# f28p65x_trig_regs register map
Vendor: Texas Instruments
Peripheral module from a debugger description file (folder C2000).
Address unit: 16 bits
Registers are 32-bit, read-write, no defined reset value unless marked. A register's access mark holds for its fields unless they carry their own. Offsets are as the file gives them; lines under a group give offsets from that group; [hi:lo] are bit positions; {n}, {i} and the like mark numbered series; 'fields as' and 'values as' point back to an identical list; <NAME> marks a mode.

## TRIG_REGS — TRIG Registers
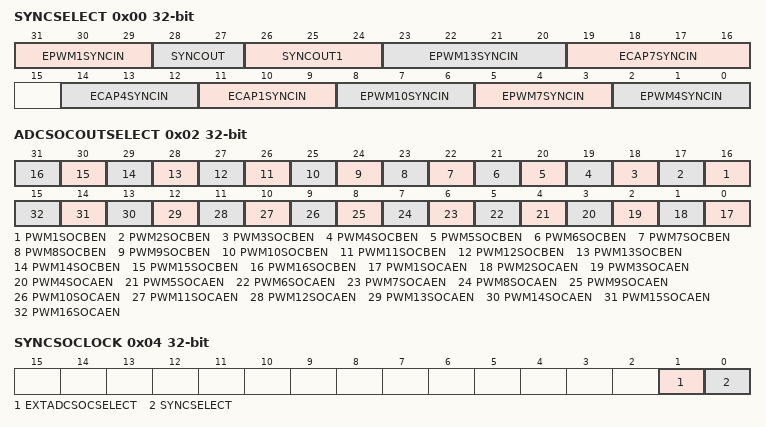
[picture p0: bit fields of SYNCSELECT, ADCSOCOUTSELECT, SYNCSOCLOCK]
0x00 SYNCSELECT — Sync Input and Output Select Register
  [31:29] EPWM1SYNCIN — Selects Sync Input Source for EPWM1
  [28:27] SYNCOUT — Select Syncout Source
  [26:24] SYNCOUT1 — Select Syncout Source
  [23:20] EPWM13SYNCIN — Selects Sync Input Source for EPWM13
  [19:16] ECAP7SYNCIN — Selects Sync Input Source for ECAP7
  [14:12] ECAP4SYNCIN — Selects Sync Input Source for ECAP4
  [11:9] ECAP1SYNCIN — Selects Sync Input Source for ECAP1
  [8:6] EPWM10SYNCIN — Selects Sync Input Source for EPWM10
  [5:3] EPWM7SYNCIN — Selects Sync Input Source for EPWM7
  [2:0] EPWM4SYNCIN — Selects Sync Input Source for EPWM4
0x02 ADCSOCOUTSELECT — External ADC (Off Chip) SOC Select Register
  [n+15] PWM{n}SOCBEN (n=1..16) — PWM{n}SOCBEN Enable for ADCSOCBOn
  [n-1] PWM{n}SOCAEN (n=1..16) — PWM{n}SOCAEN Enable for ADCSOCAOn
0x04 SYNCSOCLOCK — SYNCSEL and EXTADCSOC Select Lock register
  [1] EXTADCSOCSELECT — EXTADCSOCSEL Register Lock bit
  [0] SYNCSELECT — SYNCSEL Register Lock bit
